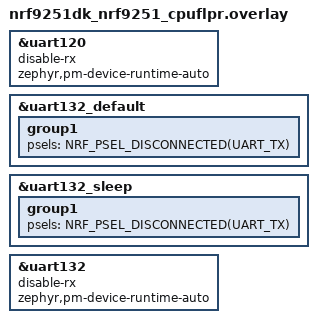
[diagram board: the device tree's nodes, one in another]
/*
 * Copyright (c) 2026 Nordic Semiconductor ASA
 *
 * SPDX-License-Identifier: LicenseRef-Nordic-5-Clause
 */

/* Disable UART while not in use. */
&uart120 {
	disable-rx;
	zephyr,pm-device-runtime-auto;
};

/* The nordic-flpr-uart13x snippet (used by CI) makes uart132 the console,
 * prevent it from using p2.05.
 */
&uart132_default {
	/delete-node/ group1;
	/delete-node/ group3;

	group1 {
		psels = <NRF_PSEL_DISCONNECTED(UART_TX)>;
	};
};

&uart132_sleep {
	/delete-node/ group1;

	group1 {
		psels = <NRF_PSEL_DISCONNECTED(UART_TX)>;
	};
};

&uart132 {
	disable-rx;
	zephyr,pm-device-runtime-auto;
};
